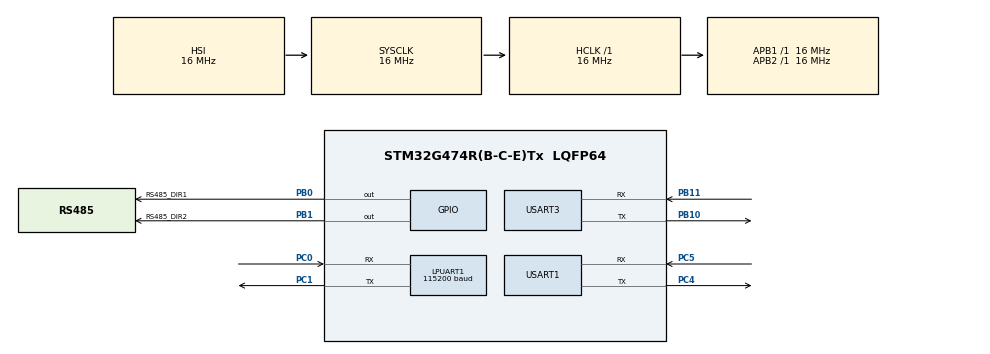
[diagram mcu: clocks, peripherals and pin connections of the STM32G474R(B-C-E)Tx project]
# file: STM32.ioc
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Mcu.Family=STM32G4
Mcu.Name=STM32G474R(B-C-E)Tx
Mcu.Package=LQFP64
LPUART1.BaudRate=115200
LPUART1.VirtualMode-Asynchronous=VM_ASYNC
NVIC.LPUART1_IRQn=true\:0\:0\:false\:false\:true\:true\:true\:true
NVIC.PriorityGroup=NVIC_PRIORITYGROUP_4
NVIC.USART1_IRQn=true\:0\:0\:false\:false\:true\:true\:true\:true
NVIC.USART3_IRQn=true\:0\:0\:false\:false\:true\:true\:true\:true
PA13.Mode=Serial_Wire
PA13.Signal=SYS_JTMS-SWDIO
PA14.Mode=Serial_Wire
PA14.Signal=SYS_JTCK-SWCLK
PB0.GPIO_Label=RS485_DIR1
PB0.Signal=GPIO_Output
PB1.GPIO_Label=RS485_DIR2
PB1.Signal=GPIO_Output
PB10.Mode=Asynchronous
PB10.Signal=USART3_TX
PB11.Mode=Asynchronous
PB11.Signal=USART3_RX
PC0.Mode=Asynchronous
PC0.Signal=LPUART1_RX
PC1.Mode=Asynchronous
PC1.Signal=LPUART1_TX
PC4.Mode=Asynchronous
PC4.Signal=USART1_TX
PC5.Mode=Asynchronous
PC5.Signal=USART1_RX
ProjectManager.HeapSize=0x2000
ProjectManager.StackSize=0x400
ProjectManager.TargetToolchain=STM32CubeIDE
RCC.AHBFreq_Value=16000000
RCC.APB1Freq_Value=16000000
RCC.APB1TimFreq_Value=16000000
RCC.APB2Freq_Value=16000000
RCC.APB2TimFreq_Value=16000000
RCC.CortexFreq_Value=16000000
RCC.EXTERNAL_CLOCK_VALUE=12288000
RCC.HCLKFreq_Value=16000000
RCC.HSE_VALUE=8000000
RCC.HSI48_VALUE=48000000
RCC.HSI_VALUE=16000000
RCC.LSE_VALUE=32768
RCC.SYSCLKFreq_VALUE=16000000
RCC.USBFreq_Value=64000000
RCC.VCOOutputFreq_Value=128000000
USART1.VirtualMode-Asynchronous=VM_ASYNC
USART3.VirtualMode-Asynchronous=VM_ASYNC
VP_SYS_VS_DBSignals.Mode=DisableDeadBatterySignals
board=custom

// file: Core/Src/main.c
/* USER CODE BEGIN Header */
/**
  ******************************************************************************
  * @file           : main.c
  * @brief          : Main program body
  ******************************************************************************
  * @attention
  *
  * Copyright (c) 2026 STMicroelectronics.
  * All rights reserved.
  *
  * This software is licensed under terms that can be found in the LICENSE file
  * in the root directory of this software component.
  * If no LICENSE file comes with this software, it is provided AS-IS.
  *
  ******************************************************************************
  */
/* USER CODE END Header */
#include "main.h"

/* USER CODE BEGIN Includes */
#include "mwrs_control.h"

/* USER CODE END Includes */

UART_HandleTypeDef hlpuart1;
UART_HandleTypeDef huart1;
UART_HandleTypeDef huart3;

void SystemClock_Config(void);
static void MX_GPIO_Init(void);
static void MX_LPUART1_UART_Init(void);
static void MX_USART1_UART_Init(void);
static void MX_USART3_UART_Init(void);

int main(void)
{

  /* MCU Configuration--------------------------------------------------------*/

  /* Reset of all peripherals, Initializes the Flash interface and the Systick. */
  HAL_Init();

  /* Configure the system clock */
  SystemClock_Config();

  /* Initialize all configured peripherals */
  MX_GPIO_Init();
  MX_LPUART1_UART_Init();
  MX_USART1_UART_Init();
  MX_USART3_UART_Init();
  /* USER CODE BEGIN 2 */
  MWRS_Control_Init();

  /* USER CODE END 2 */

  /* Infinite loop */
  while (1)
  {

    /* USER CODE BEGIN 3 */
    MWRS_Control_Process();
  }
  /* USER CODE END 3 */
}

void SystemClock_Config(void)
{
  RCC_OscInitTypeDef RCC_OscInitStruct = {0};
  RCC_ClkInitTypeDef RCC_ClkInitStruct = {0};

  /** Configure the main internal regulator output voltage
  */
  HAL_PWREx_ControlVoltageScaling(PWR_REGULATOR_VOLTAGE_SCALE1);

  /** Initializes the RCC Oscillators according to the specified parameters
  * in the RCC_OscInitTypeDef structure.
  */
  RCC_OscInitStruct.OscillatorType = RCC_OSCILLATORTYPE_HSI;
  RCC_OscInitStruct.HSIState = RCC_HSI_ON;
  RCC_OscInitStruct.HSICalibrationValue = RCC_HSICALIBRATION_DEFAULT;
  RCC_OscInitStruct.PLL.PLLState = RCC_PLL_NONE;
  if (HAL_RCC_OscConfig(&RCC_OscInitStruct) != HAL_OK)
  {
    Error_Handler();
  }

  /** Initializes the CPU, AHB and APB buses clocks
  */
  RCC_ClkInitStruct.ClockType = RCC_CLOCKTYPE_HCLK|RCC_CLOCKTYPE_SYSCLK
                              |RCC_CLOCKTYPE_PCLK1|RCC_CLOCKTYPE_PCLK2;
  RCC_ClkInitStruct.SYSCLKSource = RCC_SYSCLKSOURCE_HSI;
  RCC_ClkInitStruct.AHBCLKDivider = RCC_SYSCLK_DIV1;
  RCC_ClkInitStruct.APB1CLKDivider = RCC_HCLK_DIV1;
  RCC_ClkInitStruct.APB2CLKDivider = RCC_HCLK_DIV1;

  if (HAL_RCC_ClockConfig(&RCC_ClkInitStruct, FLASH_LATENCY_0) != HAL_OK)
  {
    Error_Handler();
  }
}

static void MX_LPUART1_UART_Init(void)
{

  /* ST-LINK V3 VCP link to Raspberry Pi: 115200, 8N1. */
  hlpuart1.Instance = LPUART1;
  hlpuart1.Init.BaudRate = 115200;
  hlpuart1.Init.WordLength = UART_WORDLENGTH_8B;
  hlpuart1.Init.StopBits = UART_STOPBITS_1;
  hlpuart1.Init.Parity = UART_PARITY_NONE;
  hlpuart1.Init.Mode = UART_MODE_TX_RX;
  hlpuart1.Init.HwFlowCtl = UART_HWCONTROL_NONE;
  hlpuart1.Init.OneBitSampling = UART_ONE_BIT_SAMPLE_DISABLE;
  hlpuart1.Init.ClockPrescaler = UART_PRESCALER_DIV1;
  hlpuart1.AdvancedInit.AdvFeatureInit = UART_ADVFEATURE_NO_INIT;
  if (HAL_UART_Init(&hlpuart1) != HAL_OK)
  {
    Error_Handler();
  }
  if (HAL_UARTEx_SetTxFifoThreshold(&hlpuart1, UART_TXFIFO_THRESHOLD_1_8) != HAL_OK)
  {
    Error_Handler();
  }
  if (HAL_UARTEx_SetRxFifoThreshold(&hlpuart1, UART_RXFIFO_THRESHOLD_1_8) != HAL_OK)
  {
    Error_Handler();
  }
  if (HAL_UARTEx_DisableFifoMode(&hlpuart1) != HAL_OK)
  {
    Error_Handler();
  }

}

static void MX_USART1_UART_Init(void)
{

  /* MKS SERVO57D Modbus RTU bus. Drivers must be configured for 115200, 8N1. */
  huart1.Instance = USART1;
  huart1.Init.BaudRate = 115200;
  huart1.Init.WordLength = UART_WORDLENGTH_8B;
  huart1.Init.StopBits = UART_STOPBITS_1;
  huart1.Init.Parity = UART_PARITY_NONE;
  huart1.Init.Mode = UART_MODE_TX_RX;
  huart1.Init.HwFlowCtl = UART_HWCONTROL_NONE;
  huart1.Init.OverSampling = UART_OVERSAMPLING_16;
  huart1.Init.OneBitSampling = UART_ONE_BIT_SAMPLE_DISABLE;
  huart1.Init.ClockPrescaler = UART_PRESCALER_DIV1;
  huart1.AdvancedInit.AdvFeatureInit = UART_ADVFEATURE_NO_INIT;
  if (HAL_UART_Init(&huart1) != HAL_OK)
  {
    Error_Handler();
  }
  if (HAL_UARTEx_SetTxFifoThreshold(&huart1, UART_TXFIFO_THRESHOLD_1_8) != HAL_OK)
  {
    Error_Handler();
  }
  if (HAL_UARTEx_SetRxFifoThreshold(&huart1, UART_RXFIFO_THRESHOLD_1_8) != HAL_OK)
  {
    Error_Handler();
  }
  if (HAL_UARTEx_DisableFifoMode(&huart1) != HAL_OK)
  {
    Error_Handler();
  }

}

static void MX_USART3_UART_Init(void)
{

  /* BLD-305S Modbus RTU bus: the manufacturer manual specifies 115200, 8N1. */
  huart3.Instance = USART3;
  huart3.Init.BaudRate = 115200;
  huart3.Init.WordLength = UART_WORDLENGTH_8B;
  huart3.Init.StopBits = UART_STOPBITS_1;
  huart3.Init.Parity = UART_PARITY_NONE;
  huart3.Init.Mode = UART_MODE_TX_RX;
  huart3.Init.HwFlowCtl = UART_HWCONTROL_NONE;
  huart3.Init.OverSampling = UART_OVERSAMPLING_16;
  huart3.Init.OneBitSampling = UART_ONE_BIT_SAMPLE_DISABLE;
  huart3.Init.ClockPrescaler = UART_PRESCALER_DIV1;
  huart3.AdvancedInit.AdvFeatureInit = UART_ADVFEATURE_NO_INIT;
  if (HAL_UART_Init(&huart3) != HAL_OK)
  {
    Error_Handler();
  }
  if (HAL_UARTEx_SetTxFifoThreshold(&huart3, UART_TXFIFO_THRESHOLD_1_8) != HAL_OK)
  {
    Error_Handler();
  }
  if (HAL_UARTEx_SetRxFifoThreshold(&huart3, UART_RXFIFO_THRESHOLD_1_8) != HAL_OK)
  {
    Error_Handler();
  }
  if (HAL_UARTEx_DisableFifoMode(&huart3) != HAL_OK)
  {
    Error_Handler();
  }

}

static void MX_GPIO_Init(void)
{
  GPIO_InitTypeDef GPIO_InitStruct = {0};

  /* GPIO Ports Clock Enable */
  __HAL_RCC_GPIOC_CLK_ENABLE();
  __HAL_RCC_GPIOB_CLK_ENABLE();
  __HAL_RCC_GPIOA_CLK_ENABLE();

  /*Configure GPIO pin Output Level */
  HAL_GPIO_WritePin(GPIOB, RS485_DIR1_Pin|RS485_DIR2_Pin, GPIO_PIN_RESET);

  /*Configure GPIO pins : RS485_DIR1_Pin RS485_DIR2_Pin */
  GPIO_InitStruct.Pin = RS485_DIR1_Pin|RS485_DIR2_Pin;
  GPIO_InitStruct.Mode = GPIO_MODE_OUTPUT_PP;
  GPIO_InitStruct.Pull = GPIO_NOPULL;
  GPIO_InitStruct.Speed = GPIO_SPEED_FREQ_LOW;
  HAL_GPIO_Init(GPIOB, &GPIO_InitStruct);

}

void Error_Handler(void)
{
  __disable_irq();
  while (1)
  {
  }
}
